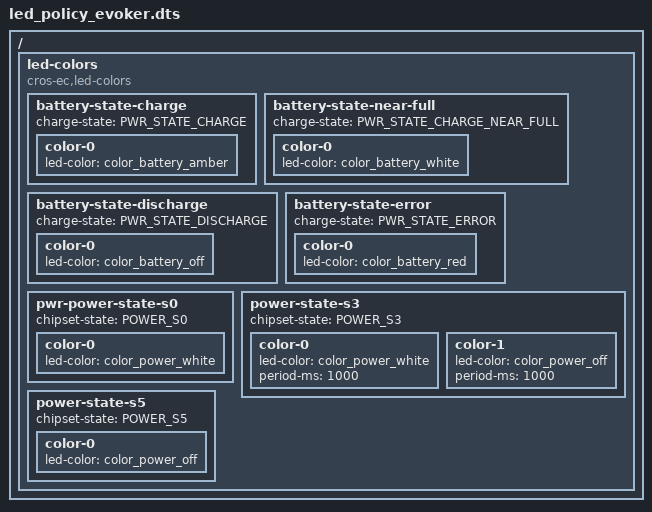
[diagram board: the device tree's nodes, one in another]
#include <dt-bindings/battery.h>

/ {
	led-colors {
		compatible = "cros-ec,led-colors";

		battery-state-charge {
			charge-state = "PWR_STATE_CHARGE";

			color-0 {
				led-color = <&color_battery_amber>;
			};
		};

		battery-state-near-full {
			charge-state = "PWR_STATE_CHARGE_NEAR_FULL";

			color-0 {
				led-color = <&color_battery_white>;
			};
		};

		battery-state-discharge {
			charge-state = "PWR_STATE_DISCHARGE";

			color-0 {
				led-color = <&color_battery_off>;
			};
		};

		battery-state-error {
			charge-state = "PWR_STATE_ERROR";

			color-0 {
				led-color = <&color_battery_red>;
			};
		};

		pwr-power-state-s0 {
			chipset-state = "POWER_S0";

			color-0 {
				led-color = <&color_power_white>;
			};
		};

		power-state-s3 {
			chipset-state = "POWER_S3";

			color-0 {
				led-color = <&color_power_white>;
				period-ms = <1000>;
			};

			color-1 {
				led-color = <&color_power_off>;
				period-ms = <1000>;
			};
		};

		power-state-s5 {
			chipset-state = "POWER_S5";
			color-0 {
				led-color = <&color_power_off>;
			};
		};
	};
};
